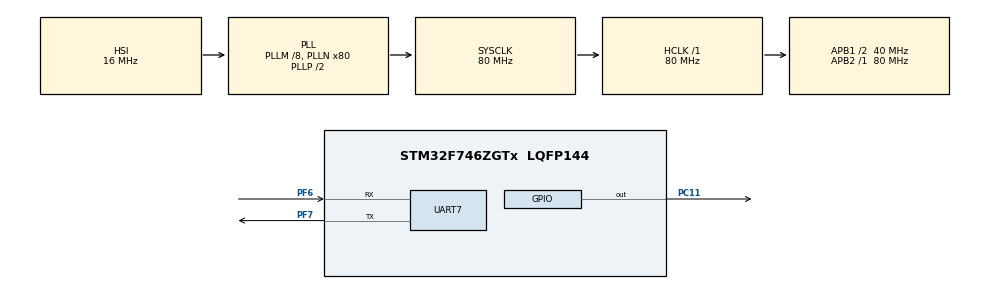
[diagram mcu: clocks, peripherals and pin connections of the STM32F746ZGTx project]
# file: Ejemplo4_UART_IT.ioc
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Mcu.Family=STM32F7
Mcu.Name=STM32F746ZGTx
Mcu.Package=LQFP144
NVIC.PriorityGroup=NVIC_PRIORITYGROUP_4
NVIC.UART7_IRQn=true\:0\:0\:false\:false\:true\:true\:true\:true
PA13.Mode=Serial_Wire
PA13.Signal=SYS_JTMS-SWDIO
PA14.Mode=Serial_Wire
PA14.Signal=SYS_JTCK-SWCLK
PC11.Signal=GPIO_Output
PC14/OSC32_IN.Mode=LSE-External-Oscillator
PC14/OSC32_IN.Signal=RCC_OSC32_IN
PC15/OSC32_OUT.Mode=LSE-External-Oscillator
PC15/OSC32_OUT.Signal=RCC_OSC32_OUT
PF6.Mode=Asynchronous
PF6.Signal=UART7_RX
PF7.Mode=Asynchronous
PF7.Signal=UART7_TX
PH0/OSC_IN.Mode=HSE-External-Oscillator
PH0/OSC_IN.Signal=RCC_OSC_IN
PH1/OSC_OUT.Mode=HSE-External-Oscillator
PH1/OSC_OUT.Signal=RCC_OSC_OUT
ProjectManager.HeapSize=0x200
ProjectManager.StackSize=0x400
ProjectManager.TargetToolchain=STM32CubeIDE
RCC.48MHZClocksFreq_Value=24000000
RCC.AHBFreq_Value=80000000
RCC.APB1CLKDivider=RCC_HCLK_DIV2
RCC.APB1Freq_Value=40000000
RCC.APB1TimFreq_Value=80000000
RCC.APB2Freq_Value=80000000
RCC.APB2TimFreq_Value=80000000
RCC.CortexFreq_Value=80000000
RCC.HCLKFreq_Value=80000000
RCC.HSE_VALUE=8000000
RCC.HSI_VALUE=16000000
RCC.PLLM=8
RCC.PLLMUL=RCC_PLL_MUL9
RCC.PLLN=80
RCC.PRESCALERUSB=RCC_USBCLKSOURCE_PLL_DIV1_5
RCC.SYSCLKFreq_VALUE=80000000
RCC.SYSCLKSource=RCC_SYSCLKSOURCE_PLLCLK
RCC.SYSCLKSourceVirtual=RCC_SYSCLKSOURCE_PLLCLK
RCC.USBFreq_Value=80000000
RCC.VCOOutputFreq_Value=160000000
board=NUCLEO-F746ZG

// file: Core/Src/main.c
/* USER CODE BEGIN Header */
/**
  ******************************************************************************
  * @file           : main.c
  * @brief          : Main program body
  ******************************************************************************
  * @attention
  *
  * Copyright (c) 2023 STMicroelectronics.
  * All rights reserved.
  *
  * This software is licensed under terms that can be found in the LICENSE file
  * in the root directory of this software component.
  * If no LICENSE file comes with this software, it is provided AS-IS.
  *
  ******************************************************************************
  */
/* USER CODE END Header */
#include "main.h"

/* USER CODE BEGIN PM */
 uint8_t Rx[1];
 uint8_t Tx_ACK[]="ACK OK"
/* USER CODE END PM */;

UART_HandleTypeDef huart7;

void SystemClock_Config(void);
static void MX_GPIO_Init(void);
static void MX_UART7_Init(void);

int main(void)
{

  /* MCU Configuration--------------------------------------------------------*/

  /* Reset of all peripherals, Initializes the Flash interface and the Systick. */
  HAL_Init();

  /* Configure the system clock */
  SystemClock_Config();

  /* Initialize all configured peripherals */
  MX_GPIO_Init();
  MX_UART7_Init();
  /* USER CODE BEGIN 2 */

  HAL_UART_Receive_IT(&huart7, Rx, sizeof(Rx));

  /* USER CODE END 2 */

  /* Infinite loop */
  while (1)
  {

  }
}

void SystemClock_Config(void)
{
  RCC_OscInitTypeDef RCC_OscInitStruct = {0};
  RCC_ClkInitTypeDef RCC_ClkInitStruct = {0};

  /** Configure LSE Drive Capability
  */
  HAL_PWR_EnableBkUpAccess();

  /** Configure the main internal regulator output voltage
  */
  __HAL_RCC_PWR_CLK_ENABLE();
  __HAL_PWR_VOLTAGESCALING_CONFIG(PWR_REGULATOR_VOLTAGE_SCALE3);

  /** Initializes the RCC Oscillators according to the specified parameters
  * in the RCC_OscInitTypeDef structure.
  */
  RCC_OscInitStruct.OscillatorType = RCC_OSCILLATORTYPE_HSI;
  RCC_OscInitStruct.HSIState = RCC_HSI_ON;
  RCC_OscInitStruct.HSICalibrationValue = RCC_HSICALIBRATION_DEFAULT;
  RCC_OscInitStruct.PLL.PLLState = RCC_PLL_ON;
  RCC_OscInitStruct.PLL.PLLSource = RCC_PLLSOURCE_HSI;
  RCC_OscInitStruct.PLL.PLLM = 8;
  RCC_OscInitStruct.PLL.PLLN = 80;
  RCC_OscInitStruct.PLL.PLLP = RCC_PLLP_DIV2;
  RCC_OscInitStruct.PLL.PLLQ = 2;
  if (HAL_RCC_OscConfig(&RCC_OscInitStruct) != HAL_OK)
  {
    Error_Handler();
  }

  /** Initializes the CPU, AHB and APB buses clocks
  */
  RCC_ClkInitStruct.ClockType = RCC_CLOCKTYPE_HCLK|RCC_CLOCKTYPE_SYSCLK
                              |RCC_CLOCKTYPE_PCLK1|RCC_CLOCKTYPE_PCLK2;
  RCC_ClkInitStruct.SYSCLKSource = RCC_SYSCLKSOURCE_PLLCLK;
  RCC_ClkInitStruct.AHBCLKDivider = RCC_SYSCLK_DIV1;
  RCC_ClkInitStruct.APB1CLKDivider = RCC_HCLK_DIV2;
  RCC_ClkInitStruct.APB2CLKDivider = RCC_HCLK_DIV1;

  if (HAL_RCC_ClockConfig(&RCC_ClkInitStruct, FLASH_LATENCY_2) != HAL_OK)
  {
    Error_Handler();
  }
}

static void MX_UART7_Init(void)
{

  huart7.Instance = UART7;
  huart7.Init.BaudRate = 115200;
  huart7.Init.WordLength = UART_WORDLENGTH_8B;
  huart7.Init.StopBits = UART_STOPBITS_1;
  huart7.Init.Parity = UART_PARITY_NONE;
  huart7.Init.Mode = UART_MODE_TX_RX;
  huart7.Init.HwFlowCtl = UART_HWCONTROL_NONE;
  huart7.Init.OverSampling = UART_OVERSAMPLING_16;
  huart7.Init.OneBitSampling = UART_ONE_BIT_SAMPLE_DISABLE;
  huart7.AdvancedInit.AdvFeatureInit = UART_ADVFEATURE_NO_INIT;
  if (HAL_UART_Init(&huart7) != HAL_OK)
  {
    Error_Handler();
  }

}

static void MX_GPIO_Init(void)
{
  GPIO_InitTypeDef GPIO_InitStruct = {0};

  /* GPIO Ports Clock Enable */
  __HAL_RCC_GPIOC_CLK_ENABLE();
  __HAL_RCC_GPIOF_CLK_ENABLE();
  __HAL_RCC_GPIOH_CLK_ENABLE();
  __HAL_RCC_GPIOA_CLK_ENABLE();

  /*Configure GPIO pin Output Level */
  HAL_GPIO_WritePin(GPIOC, GPIO_PIN_11, GPIO_PIN_RESET);

  /*Configure GPIO pin : PC11 */
  GPIO_InitStruct.Pin = GPIO_PIN_11;
  GPIO_InitStruct.Mode = GPIO_MODE_OUTPUT_PP;
  GPIO_InitStruct.Pull = GPIO_NOPULL;
  GPIO_InitStruct.Speed = GPIO_SPEED_FREQ_LOW;
  HAL_GPIO_Init(GPIOC, &GPIO_InitStruct);

}

/* USER CODE BEGIN 4 */
void HAL_UART_RxCpltCallback(UART_HandleTypeDef *huart)
{
	if(huart->Instance==UART7){
				HAL_UART_Transmit_IT(&huart7, Tx_ACK, sizeof(Tx_ACK));
			}
				switch (Rx[0]) {
				case '1':
					HAL_GPIO_WritePin(GPIOC, GPIO_PIN_11, GPIO_PIN_SET);
					break;
				case '0':
				HAL_GPIO_WritePin(GPIOC, GPIO_PIN_11, GPIO_PIN_RESET);
				    break;
				default:
					break;
				}
	     HAL_UART_Receive_IT(&huart7, Rx, sizeof(Rx));

}
/* USER CODE END 4 */

void Error_Handler(void)
{
  __disable_irq();
  while (1)
  {
  }
}
